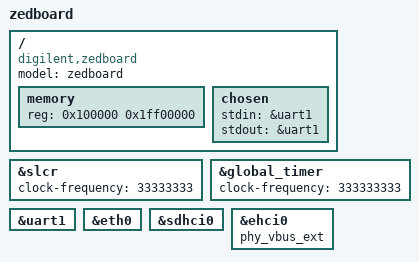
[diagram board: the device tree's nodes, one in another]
/*-
 * Copyright (c) 2016 The FreeBSD Foundation
 * All rights reserved.
 *
 * Redistribution and use in source and binary forms, with or without
 * modification, are permitted provided that the following conditions
 * are met:
 * 1. Redistributions of source code must retain the above copyright
 *    notice, this list of conditions and the following disclaimer.
 * 2. Redistributions in binary form must reproduce the above copyright
 *    notice, this list of conditions and the following disclaimer in the
 *    documentation and/or other materials provided with the distribution.
 *
 * THIS SOFTWARE IS PROVIDED BY THE AUTHOR AND CONTRIBUTORS ``AS IS'' AND
 * ANY EXPRESS OR IMPLIED WARRANTIES, INCLUDING, BUT NOT LIMITED TO, THE
 * IMPLIED WARRANTIES OF MERCHANTABILITY AND FITNESS FOR A PARTICULAR PURPOSE
 * ARE DISCLAIMED. IN NO EVENT SHALL THE AUTHOR OR CONTRIBUTORS BE LIABLE
 * FOR ANY DIRECT, INDIRECT, INCIDENTAL, SPECIAL, EXEMPLARY, OR CONSEQUENTIAL
 * DAMAGES (INCLUDING, BUT NOT LIMITED TO, PROCUREMENT OF SUBSTITUTE GOODS
 * OR SERVICES; LOSS OF USE, DATA, OR PROFITS; OR BUSINESS INTERRUPTION)
 * HOWEVER CAUSED AND ON ANY THEORY OF LIABILITY, WHETHER IN CONTRACT, STRICT
 * LIABILITY, OR TORT (INCLUDING NEGLIGENCE OR OTHERWISE) ARISING IN ANY WAY
 * OUT OF THE USE OF THIS SOFTWARE, EVEN IF ADVISED OF THE POSSIBILITY OF
 * SUCH DAMAGE.
 * 
 * $FreeBSD$
 */
/dts-v1/;
/include/ "zynq-7000.dtsi"

/ {
	model = "zedboard";
	compatible = "digilent,zedboard", "xlnx,zynq-7000";

	memory {
		// First megabyte isn't accessible by all interconnect masters.
		device_type = "memory";
		reg = <0x100000 0x1ff00000>;	/* 511MB RAM at 0x100000 */
	};

	chosen {
		stdin = &uart1;
		stdout = &uart1;
	};
};

&slcr {
	clock-frequency = <33333333>; // 33Mhz PS_CLK
};

&global_timer {
	clock-frequency = <333333333>; // 333Mhz
};

&uart1 {
	status = "okay";
};

&eth0 {
	status = "okay";
};

&sdhci0 {
	status = "okay";
};

&ehci0 {
	status = "okay";
	phy_vbus_ext;
};

